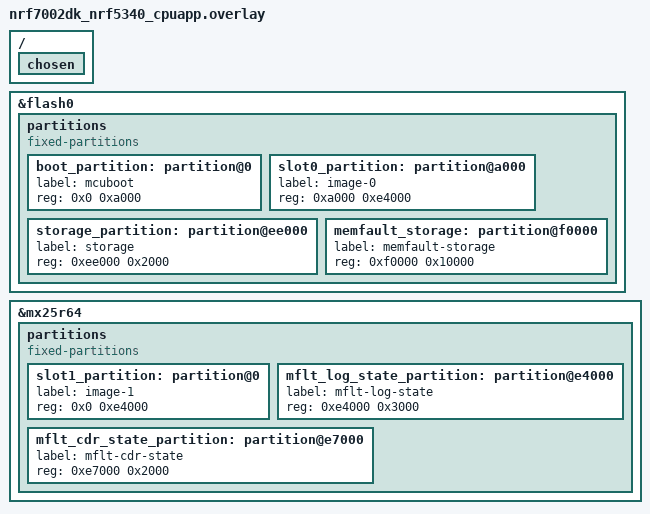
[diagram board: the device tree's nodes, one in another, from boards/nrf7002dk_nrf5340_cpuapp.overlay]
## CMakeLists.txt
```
#
# Copyright (c) 2026 Nordic Semiconductor
#
# SPDX-License-Identifier: LicenseRef-Nordic-5-Clause
#

cmake_minimum_required(VERSION 3.20.0)

# Register zego modules: button, led, wifi, network, wifi_ble_prov, memonitor, ux, ntp, factory_reset.
get_filename_component(ZEGO_BUTTON_DIR ${CMAKE_CURRENT_SOURCE_DIR}/../zego/bricks/button REALPATH)
get_filename_component(ZEGO_LED_DIR ${CMAKE_CURRENT_SOURCE_DIR}/../zego/bricks/led REALPATH)
get_filename_component(ZEGO_WIFI_DIR ${CMAKE_CURRENT_SOURCE_DIR}/../zego/bricks/wifi REALPATH)
get_filename_component(ZEGO_NETWORK_DIR ${CMAKE_CURRENT_SOURCE_DIR}/../zego/bricks/network REALPATH)
get_filename_component(ZEGO_WIFI_BLE_PROV_DIR ${CMAKE_CURRENT_SOURCE_DIR}/../zego/bricks/wifi_ble_prov REALPATH)
get_filename_component(ZEGO_MEMONITOR_DIR ${CMAKE_CURRENT_SOURCE_DIR}/../zego/bricks/memonitor REALPATH)
get_filename_component(ZEGO_UX_DIR ${CMAKE_CURRENT_SOURCE_DIR}/../zego/bricks/ux REALPATH)
get_filename_component(ZEGO_NTP_DIR ${CMAKE_CURRENT_SOURCE_DIR}/../zego/bricks/ntp REALPATH)
get_filename_component(ZEGO_FACTORY_RESET_DIR ${CMAKE_CURRENT_SOURCE_DIR}/../zego/bricks/factory_reset REALPATH)
list(APPEND EXTRA_ZEPHYR_MODULES ${ZEGO_BUTTON_DIR} ${ZEGO_LED_DIR} ${ZEGO_WIFI_DIR} ${ZEGO_NETWORK_DIR} ${ZEGO_WIFI_BLE_PROV_DIR} ${ZEGO_MEMONITOR_DIR} ${ZEGO_UX_DIR} ${ZEGO_NTP_DIR} ${ZEGO_FACTORY_RESET_DIR})

find_package(Zephyr REQUIRED HINTS $ENV{ZEPHYR_BASE})
project(memfault-nrf7002dk)

# Generate hex files from pem files for app HTTPS client
if(CONFIG_APP_HTTPS_CLIENT_MODULE)
    set(gen_dir ${CMAKE_CURRENT_BINARY_DIR}/certs)
    zephyr_include_directories(${gen_dir})
    generate_inc_file_for_target(
        app
        src/modules/app_https_client/cert/Comodo-AAA-Certificate-Services.pem
        ${gen_dir}/Comodo-AAA-Certificate-Services.pem.inc
    )
endif()


zephyr_include_directories(${CMAKE_CURRENT_SOURCE_DIR}/src)
zephyr_include_directories(${CMAKE_CURRENT_SOURCE_DIR}/src/modules/app_memfault/config)

# APP_VERSION_STRING, PRD_VERSION, SPECS_VERSION set by zego/wifi/CMakeLists.txt
target_sources(app PRIVATE src/main.c)

# Module subdirectories (SMF+zbus modular architecture)
# button module now provided by zego/button (EXTRA_ZEPHYR_MODULES above)
# Shared network module provided by zego/network (EXTRA_ZEPHYR_MODULES above);
# app shim (net_event_mgmt.c) defines NETWORK_CHAN, declares WIFI_CHAN, overrides weak callbacks.
if(CONFIG_ZEGO_NETWORK)
    add_subdirectory(src/modules/network)
endif()
if(CONFIG_ZEGO_UX)
    add_subdirectory(src/modules/ux)
endif()
if(CONFIG_APP_MEMFAULT_MODULE)
    add_subdirectory(src/modules/app_memfault)
endif()
if(CONFIG_APP_HTTPS_CLIENT_MODULE)
    add_subdirectory(src/modules/app_https_client)
endif()
if(CONFIG_APP_MQTT_CLIENT_MODULE)
    add_subdirectory(src/modules/app_mqtt_client)
endif()

# ntp module now provided by zego/ntp (EXTRA_ZEPHYR_MODULES above); app shim
# (net_event_mgmt.c) publishes ZEGO_NTP_NET_CHAN from its weak-hook overrides.

# zego/wifi_ble_prov handles BLE provisioning as an EXTRA_ZEPHYR_MODULE (no extra target_link_libraries needed).
# zego/led is registered above and provides LED_CMD_CHAN; consumed by zego/ux.
```

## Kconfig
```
#
# Copyright (c) 2026 Nordic Semiconductor ASA
#
# SPDX-License-Identifier: LicenseRef-Nordic-5-Clause
#

menu "Application configuration"

module = APP_MAIN
module-str = Application main
source "${ZEPHYR_BASE}/subsys/logging/Kconfig.template.log_config"

rsource "src/modules/button/Kconfig.button"
rsource "src/modules/network/Kconfig"
rsource "src/modules/heap_monitor/Kconfig.heap_monitor"
rsource "src/modules/wifi_prov_over_ble/Kconfig.wifi_prov_over_ble"
rsource "src/modules/app_memfault/Kconfig.app_memfault"
rsource "src/modules/app_https_client/Kconfig.app_https_client"
rsource "src/modules/app_mqtt_client/Kconfig.app_mqtt_client"
rsource "src/modules/ntp/Kconfig.ntp"

rsource "src/modules/network/Kconfig.defaults"
rsource "src/modules/heap_monitor/Kconfig.defaults"
rsource "src/modules/wifi_prov_over_ble/Kconfig.defaults"
rsource "src/modules/app_memfault/Kconfig.defaults"
rsource "src/modules/app_https_client/Kconfig.defaults"
rsource "src/modules/app_mqtt_client/Kconfig.defaults"
rsource "src/modules/ntp/Kconfig.defaults"

endmenu

source "Kconfig.zephyr"
```

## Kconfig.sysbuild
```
#
# Copyright (c) 2024 Nordic Semiconductor
#
# SPDX-License-Identifier: LicenseRef-Nordic-5-Clause
#

config WIFI_NRF70
	bool
	default y if BOARD_NRF7002DK_NRF5340_CPUAPP

# Tells sysbuild's netcore-image choice (nrf/sysbuild/Kconfig.netcore) to
# default to NETCORE_HCI_IPC on boards with a separate network core
# (nRF7002DK/nRF5340). Without this, sysbuild silently falls back to
# NETCORE_NONE and no BLE controller firmware is built for the network
# core, even though the app enables CONFIG_BT_HCI_IPC for BLE Wi-Fi
# provisioning — every reference NCS Bluetooth sample sets this in its
# own Kconfig.sysbuild (e.g. nrf/samples/bluetooth/peripheral_uart).
config NRF_DEFAULT_BLUETOOTH
	default y

# nrf/sysbuild/Kconfig.netcore only ships a built-in NETCORE_REMOTE_BOARD_NAME
# default for nrf5340dk/thingy53 — not nrf7002dk, even though nrf7002dk's
# nRF5340 is netcore-capable (SUPPORT_NETCORE already defaults to y for it).
# Without this, NETCORE_REMOTE_BOARD_NAME stays "" so the NETCORE choice's
# "if NRF_DEFAULT_BLUETOOTH && NETCORE_REMOTE_BOARD_NAME != \"\"" guard never
# matches and sysbuild falls back to NETCORE_NONE. This symbol has no Kconfig
# prompt, so it can only be set via a `default`, not a sysbuild.conf fragment.
config NETCORE_REMOTE_BOARD_NAME
	default "nrf7002dk_nrf5340_cpunet" if $(BOARD) = "nrf7002dk_nrf5340_cpuapp"

source "share/sysbuild/Kconfig"
```

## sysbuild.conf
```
#
# Copyright (c) 2025 Nordic Semiconductor ASA
#
# SPDX-License-Identifier: LicenseRef-Nordic-5-Clause
#

SB_CONFIG_BOOTLOADER_MCUBOOT=y
SB_CONFIG_PARTITION_MANAGER=n
SB_CONFIG_MERGED_HEX_FILES=y

# nRF5340 (nrf7002dk) only: the BLE controller runs on the network core
# over IPC. Build the upstream Zephyr hci_ipc sample as the netcore image
# so the Wi-Fi provisioning over BLE module can open the HCI driver.
# On nrf54lm20dk SUPPORT_NETCORE=n (single-core SoC), so this setting
# has no effect there and produces a benign Kconfig choice warning.
# kconfiglib prohibits 'select' on choice symbols, so this assignment cannot
# be made board-conditional from Kconfig.sysbuild.  The warning is harmless:
# sysbuild skips the hci_ipc image whenever SUPPORT_NETCORE=n, regardless of
# this choice assignment.  See also the MBEDTLS_PSA_CRYPTO_EXTERNAL_RNG note
# in boards/nrf7002dk_nrf5340_cpuapp.conf — same class of unfixable warning.
SB_CONFIG_NETCORE_HCI_IPC=y
```

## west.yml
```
manifest:
  version: "0.13"

  defaults:
    remote: ncs

  remotes:
    - name: ncs
      url-base: https://github.com/nrfconnect
    - name: chshzh
      url-base: https://github.com/chshzh

  projects:
    # NCS v3.4.1 — imports zephyr, bootloader, modules, nrfxlib, tools, etc.
    - name: sdk-nrf
      path: nrf
      revision: v3.4.1
      import: true
      remote: ncs
      
    # Common app modules and libraries
    - name: zego
      path: zego
      revision: v3.4.1.0
      remote: chshzh

    # Add more sibling projects as needed:
    # - name: nordic-wifi-webdash
    #   path: nordic-wifi-webdash
    #   revision: main
    #   remote: chshzh

    # - name: nordic-wifi-audio
    #   path: nordic-wifi-audio
    #   revision: main
    #   remote: chshzh

    # - name: claude
    #   path: .claude
    #   revision: main
    #   remote: chshzh
    
    - name: zview
      url: https://github.com/chshzh/zview
      revision: main
      path: modules/tools/zview
      west-commands: scripts/west-commands.yml
    

  self:
    path: nordic-wifi-memfault
```

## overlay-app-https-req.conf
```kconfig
# App HTTPS Request Test overlay configuration
# Use this overlay to enable periodic HTTPS client requests

# Enable app HTTPS client functionality
CONFIG_APP_HTTPS_CLIENT_ENABLED=y

# Configure HTTPS hostname and interval
CONFIG_APP_HTTPS_HOSTNAME="example.com"
CONFIG_APP_HTTPS_REQUEST_INTERVAL_SEC=300

# App HTTPS client logging
CONFIG_APP_HTTPS_CLIENT_LOG_LEVEL_INF=y

# mbedTLS requirements for example.com (Cloudflare-hosted, cert chain via Comodo AAA root)
# RSA: needed to verify Comodo AAA root signature (RSA/SHA1 root CA)
CONFIG_MBEDTLS_RSA_C=y
# secp384r1: needed to verify P-384 ECC key in SSL.com TLS Transit ECC CA R2
CONFIG_MBEDTLS_ECP_DP_SECP384R1_ENABLED=y
# SNI: required for Cloudflare shared-IP hosting to present the correct certificate
CONFIG_MBEDTLS_SSL_SERVER_NAME_INDICATION=y
```

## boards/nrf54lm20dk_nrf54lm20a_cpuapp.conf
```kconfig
#
# Copyright (c) 2026 Nordic Semiconductor ASA
#
# SPDX-License-Identifier: LicenseRef-Nordic-5-Clause
#

# Configuration coverage priority:
# Command line > Overlay files > project boards/<board>.conf > prj.conf > Board defconfig
# (highest)                                                              (lowest)


# This file contains only:
#   - System-level configuration that belongs to no single module
#   - Module enable/disable flags
#   - Log-level choices (cannot be set via Kconfig.defaults)
#   - Project-specific overrides that differ from module defaults
#   - Shared cross-module settings (TLS, mbedTLS)
#   - Hardware-specific memory and stack tuning
# Module-specific defaults live in each module's Kconfig.defaults file.

# nRF7002EB2 on nRF54LM20DK does not wire the SR coexistence RF switch.
CONFIG_NRF70_SR_COEX=n
CONFIG_NRF70_SR_COEX_RF_SWITCH=n

# nRF54LM20A uses RRAMC, not NVMC. The NCS flash backend
# (memfault_flash_coredump_storage.c) calls nrfx_nvmc directly and will not
# compile for this target — disable it and use the upstream RRAM backend
# (memfault_rram_backed_coredump.c) instead. That backend uses NRFX_RRAMC
# (available on nRF54LX) and reads/writes via direct memory-mapped access +
# nrf_rramc_config_set() with 16-byte (128-bit wordline) buffered writes.
# The partition must be named "memfault_coredump_partition" in pm_static.
CONFIG_MEMFAULT_NCS_INTERNAL_FLASH_BACKED_COREDUMP=n
# Renamed from CONFIG_MEMFAULT_COREDUMP_STORAGE_RRAM in the bundled Memfault SDK
# (now Nordic-specific: CONFIG_MEMFAULT_COREDUMP_STORAGE_NRF_RRAM).
CONFIG_MEMFAULT_COREDUMP_STORAGE_NRF_RRAM=y

# MPSL (Multiprotocol Service Layer) registers RADIO/TIMER/RTC interrupts at
# priority 0 with IRQ_ZERO_LATENCY so they bypass arch_irq_lock()/BASEPRI.
# On this single-core SoC those ISRs can fire inside a K_SPINLOCK block and
# change _current before z_spin_unlock_valid() completes its owner check,
# causing a false-positive "Not my spinlock" assert (RESETREAS=0x80 lockup).
# This does not occur on nRF7002DK where BLE runs on the separate CPUNET core.
# CONFIG_SPIN_VALIDATE is a debug-only feature (Zephyr docs: "adds relatively
# hefty overhead") — disable it for this target so the assert cannot fire.
CONFIG_SPIN_VALIDATE=n

# Wi-Fi provisioning over BLE uses 1M PHY only; 2M PHY is never negotiated
# and can be removed to save controller flash and RAM.
CONFIG_BT_CTLR_PHY_2M=n


# Shell - enabled for Wi-Fi diagnostics (CONFIG_MEMFAULT_SHELL=y disabled to save flash)
CONFIG_SHELL=y
CONFIG_NET_L2_WIFI_SHELL=y
CONFIG_SHELL_STACK_SIZE=8192

# Zego button + LED modules (nRF54LM20DK has enough flash)
CONFIG_ZEGO_BUTTON=y
CONFIG_ZEGO_BUTTON_NUM_BUTTONS=3
CONFIG_ZEGO_BUTTON_BACKEND_DK=y

CONFIG_ZEGO_LED=y
CONFIG_ZEGO_LED_NUM_LEDS=4
CONFIG_ZEGO_LED_BACKEND_DK=y

# memonitor: UART periodic log enabled on nRF54LM20DK (2 MB RRAM — flash headroom available).
# Left n in prj.conf for nRF7002DK where flash is at ~99%.
# CONFIG_ZEGO_MEMONITOR_LOG_PERIODIC=y
```

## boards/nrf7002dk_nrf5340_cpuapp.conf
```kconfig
#
# Copyright (c) 2026 Nordic Semiconductor ASA
#
# SPDX-License-Identifier: LicenseRef-Nordic-5-Clause
#
# Board-specific overrides for nRF7002DK (nRF5340 + nRF7002).
# Contains only settings that differ from prj.conf for this hardware.
# Configuration coverage priority:
# Command line > Overlay files > project boards/<board>.conf > prj.conf > Board defconfig
# (highest)

# Flash-backed coredump using the DTS `memfault_storage` partition (64 KB).
# CONFIG_MEMFAULT_NCS_INTERNAL_FLASH_BACKED_COREDUMP cannot be selected because
# it depends on PARTITION_MANAGER_ENABLED, which is not used for this board.
# The implementation is copied to src/modules/app_memfault/core/ to bypass the
# Kconfig dependency — the actual C code only requires PARTITION_* DTS macros.
CONFIG_MEMFAULT_COREDUMP_STORAGE_CUSTOM=y

# nRF7002DK: 2 user buttons (SW0 = Button 1, SW1 = Button 2), 2 LEDs
CONFIG_ZEGO_BUTTON=y
CONFIG_ZEGO_BUTTON_NUM_BUTTONS=2
CONFIG_ZEGO_BUTTON_BACKEND_DK=y

CONFIG_ZEGO_LED=y
CONFIG_ZEGO_LED_NUM_LEDS=2
CONFIG_ZEGO_LED_BACKEND_DK=y

# ============================================================================
# Silence the v3.3.0 Kconfig warning:
#   "MBEDTLS_PSA_CRYPTO_EXTERNAL_RNG_ALLOW_NON_CSPRNG was assigned the value
#    'y' but got the value 'n'"
# The nrf7002dk_nrf5340_cpuapp_defconfig sets this symbol to 'y'.
# NRF_SECURITY selects DISABLE_MBEDTLS_BUILTIN and sets
# MBEDTLS_CFG_FILE="nrf-config.h", making the Kconfig.mbedtls menu
# (depends on MBEDTLS_BUILTIN && MBEDTLS_CFG_FILE="config-mbedtls.h")
# invisible.  The dependency is therefore unmet.  Explicitly clearing the
# symbol here overrides the defconfig assignment so the assigned value ('n')
# matches the evaluated value ('n').
#
# A related warning ("The choice symbol MBEDTLS_PSA_CRYPTO_EXTERNAL_RNG was
# selected (set =y) but no symbol ended up as the choice selection") also
# originates from the board defconfig and cannot be silenced at the app
# level: kconfiglib does not honour "# CONFIG_CHOICE_SYMBOL is not set" for
# choice symbols, so the defconfig's choice assignment persists.  This is a
# known upstream issue (NRF_SECURITY overrides the choice via CMake, but the
# Kconfig layer is left inconsistent).  The warning is harmless; nrf_security
# always provides its own RNG implementation regardless of this choice.
# ============================================================================
# CONFIG_MBEDTLS_PSA_CRYPTO_EXTERNAL_RNG_ALLOW_NON_CSPRNG is not set
```

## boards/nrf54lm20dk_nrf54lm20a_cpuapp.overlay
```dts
/*
 * Copyright (c) 2026 Nordic Semiconductor ASA
 *
 * SPDX-License-Identifier: LicenseRef-Nordic-5-Clause
 */

&cpuapp_rram {
	/delete-node/ partitions;

	partitions {
		compatible = "fixed-partitions";
		#address-cells = <1>;
		#size-cells = <1>;

		boot_partition: partition@0 {
			label = "mcuboot";
			reg = <0x0 0x10000>;
		};

		slot0_partition: partition@10000 {
			label = "image-0";
			reg = <0x10000 0x1c3000>;
		};

		storage_partition: partition@1d3000 {
			label = "storage";
			reg = <0x1d3000 0x2000>;
		};

		memfault_coredump_partition: partition@1d5000 {
			label = "memfault-coredump-partition";
			reg = <0x1d5000 0x10000>;
		};
	};
};

&mx25r64 {
	status = "okay";
	/delete-node/ partitions;

	partitions {
		compatible = "fixed-partitions";
		#address-cells = <1>;
		#size-cells = <1>;

		slot1_partition: partition@0 {
			label = "image-1";
			reg = <0x0 0x1c3000>;
		};

		/* 12 KB dedicated partition for Memfault disconnect-time log-state blob (must fit 16 B hdr + ~80 B context + 8192 B storage) */
		mflt_log_state_partition: partition@1c3000 {
			label = "mflt-log-state";
			reg = <0x1c3000 0x3000>;
		};

		/* 8 KB dedicated partition for Memfault disconnect-time CDR (WiFi stats) blob */
		mflt_cdr_state_partition: partition@1c6000 {
			label = "mflt-cdr-state";
			reg = <0x1c6000 0x2000>;
		};
	};
};
```

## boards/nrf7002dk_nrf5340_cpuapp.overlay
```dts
/*
 * Copyright (c) 2023 Nordic Semiconductor ASA
 *
 * SPDX-License-Identifier: LicenseRef-Nordic-5-Clause
 */

/ {
	chosen {
		/delete-property/ zephyr,ipc_shm;
	};
};

&flash0 {
	/delete-node/ partitions;

	partitions {
		compatible = "fixed-partitions";
		#address-cells = <1>;
		#size-cells = <1>;

		boot_partition: partition@0 {
			label = "mcuboot";
			reg = <0x0 0xa000>;
		};

		slot0_partition: partition@a000 {
			label = "image-0";
			reg = <0xa000 0xe4000>;
		};

		storage_partition: partition@ee000 {
			label = "storage";
			reg = <0xee000 0x2000>;
		};

		memfault_storage: partition@f0000 {
			label = "memfault-storage";
			reg = <0xf0000 0x10000>;
		};
	};
};

&mx25r64 {
	status = "okay";
	/delete-node/ partitions;

	partitions {
		compatible = "fixed-partitions";
		#address-cells = <1>;
		#size-cells = <1>;

		slot1_partition: partition@0 {
			label = "image-1";
			reg = <0x0 0xe4000>; /* must match slot0 for MCUBoot swap */
		};

		/* 12 KB dedicated partition for Memfault disconnect-time log-state blob (must fit 16 B hdr + ~80 B context + 8192 B storage) */
		mflt_log_state_partition: partition@e4000 {
			label = "mflt-log-state";
			reg = <0xe4000 0x3000>;
		};

		/* 8 KB dedicated partition for Memfault disconnect-time CDR (WiFi stats) blob */
		mflt_cdr_state_partition: partition@e7000 {
			label = "mflt-cdr-state";
			reg = <0xe7000 0x2000>;
		};
	};
};
```

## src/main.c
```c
/*
 * Copyright (c) 2026 Nordic Semiconductor ASA
 *
 * SPDX-License-Identifier: LicenseRef-Nordic-5-Clause
 *
 * Application entry point. This file is intentionally neutral — all feature
 * logic lives in modules under src/modules/ and starts via SYS_INIT / zbus.
 */

#include <ctype.h>
#include <zephyr/kernel.h>
#include <zephyr/logging/log.h>
#include <zephyr/net/net_if.h>

LOG_MODULE_REGISTER(main, CONFIG_APP_MAIN_LOG_LEVEL);

int main(void)
{
	struct net_if *iface = net_if_get_default();
	struct net_linkaddr *mac_addr =
		iface ? net_if_get_link_addr(iface) : NULL;

	LOG_INF("==============================================");
	LOG_INF("Board:   %s", CONFIG_BOARD);
#if defined(CONFIG_MEMFAULT_NCS_FW_VERSION)
	LOG_INF("Version: %s", CONFIG_MEMFAULT_NCS_FW_VERSION);
#endif
	LOG_INF("Build:   %s %s", __DATE__, __TIME__);
	if (mac_addr && mac_addr->len == 6) {
		LOG_INF("MAC: %02X:%02X:%02X:%02X:%02X:%02X",
			mac_addr->addr[0], mac_addr->addr[1], mac_addr->addr[2],
			mac_addr->addr[3], mac_addr->addr[4], mac_addr->addr[5]);
	}
	LOG_INF("----------------------------------------------");
	LOG_INF("Enabled modules:");

	/* Input */
#if CONFIG_BUTTON_MODULE
	LOG_INF("  [input]  button");
#endif
	/* CONFIG_LED_MODULE_ENABLED not yet implemented */

	/* WiFi */
#if CONFIG_WIFI_STA_PROV_OVER_BLE_ENABLED
	LOG_INF("  [wifi]   wifi_sta_prov_over_ble");
#endif
	/* CONFIG_WIFI_STA_STATIC_ENABLED   not yet implemented */
	/* CONFIG_WIFI_STA_CRED_SHELL_ENABLED not yet implemented */
	/* CONFIG_WIFI_DIRECT_GO_ENABLED     not yet implemented */
	/* CONFIG_WIFI_DIRECT_CLI_ENABLED    not yet implemented */

	/* Application */
#if CONFIG_HEAPS_MONITOR
	LOG_INF("  [app]    heap_monitor");
#endif
#if CONFIG_APP_MEMFAULT_MODULE
	LOG_INF("  [app]    app_memfault");
#endif
#if CONFIG_APP_HTTPS_CLIENT_MODULE
	LOG_INF("  [app]    app_https_client  (host: %s, interval: %ds)",
		CONFIG_APP_HTTPS_HOSTNAME, CONFIG_APP_HTTPS_REQUEST_INTERVAL_SEC);
#endif
#if CONFIG_APP_MQTT_CLIENT_MODULE
	LOG_INF("  [app]    app_mqtt_client   (broker: %s, interval: %ds)",
		CONFIG_APP_MQTT_CLIENT_BROKER_HOSTNAME,
		CONFIG_APP_MQTT_CLIENT_PUBLISH_INTERVAL_SEC);
#endif
#if CONFIG_NTP_MODULE_ENABLED
	LOG_INF("  [app]    ntp               (server: %s)", CONFIG_NTP_MODULE_SERVER);
#endif
	LOG_INF("==============================================");

	for (;;) {
		k_sleep(K_FOREVER);
	}
	return 0;
}
```

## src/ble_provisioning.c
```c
/*
 * Copyright (c) 2025 Nordic Semiconductor ASA
 *
 * SPDX-License-Identifier: LicenseRef-Nordic-5-Clause
 */

#include "ble_provisioning.h"
#include <zephyr/types.h>
#include <stddef.h>
#include <string.h>
#include <errno.h>
#include <zephyr/sys/printk.h>
#include <zephyr/kernel.h>
#include <zephyr/bluetooth/bluetooth.h>
#include <zephyr/bluetooth/hci.h>
#include <zephyr/bluetooth/conn.h>
#include <zephyr/bluetooth/uuid.h>
#include <zephyr/bluetooth/gatt.h>

#include <zephyr/net/wifi.h>
#include <zephyr/net/wifi_mgmt.h>
#include <zephyr/net/wifi_credentials.h>
#include <zephyr/net/net_mgmt.h>
#include <zephyr/net/net_if.h>

#include <net/wifi_prov_core/wifi_prov_core.h>
#include <bluetooth/services/wifi_provisioning.h>

#include <zephyr/logging/log.h>
LOG_MODULE_REGISTER(ble_prov, CONFIG_MEMFAULT_SAMPLE_LOG_LEVEL);

#define WIFI_RECONNECT_DELAY_SEC 5
/* Retry every 3 minutes if reconnect fails */
#define WIFI_RECONNECT_RETRY_SEC 180

#ifdef CONFIG_WIFI_PROV_ADV_DATA_UPDATE
#define ADV_DATA_UPDATE_INTERVAL CONFIG_WIFI_PROV_ADV_DATA_UPDATE_INTERVAL
#endif /* CONFIG_WIFI_PROV_ADV_DATA_UPDATE */

#define ADV_PARAM_UPDATE_DELAY 1

#define ADV_DATA_VERSION_IDX          (BT_UUID_SIZE_128 + 0)
#define ADV_DATA_FLAG_IDX             (BT_UUID_SIZE_128 + 1)
#define ADV_DATA_FLAG_PROV_STATUS_BIT BIT(0)
#define ADV_DATA_FLAG_CONN_STATUS_BIT BIT(1)
#define ADV_DATA_RSSI_IDX             (BT_UUID_SIZE_128 + 3)

#define PROV_BT_LE_ADV_PARAM_FAST                                              \
	BT_LE_ADV_PARAM(BT_LE_ADV_OPT_CONN, BT_GAP_ADV_FAST_INT_MIN_2,         \
			BT_GAP_ADV_FAST_INT_MAX_2, NULL)

#define PROV_BT_LE_ADV_PARAM_SLOW                                              \
	BT_LE_ADV_PARAM(BT_LE_ADV_OPT_CONN, BT_GAP_ADV_SLOW_INT_MIN,           \
			BT_GAP_ADV_SLOW_INT_MAX, NULL)

#define ADV_DAEMON_STACK_SIZE 4096
#define ADV_DAEMON_PRIORITY   5

/* Work item for triggering WiFi connection after provisioning */
static struct k_work_delayable wifi_connect_work;
static bool wifi_connect_requested = false;

/* Track BLE connection state to avoid updating advertising while connected */
static struct bt_conn *current_conn = NULL;

static bool wifi_reconnect_pending = false;

static struct net_mgmt_event_callback wifi_mgmt_cb;

/* Flag to track if we've already requested connection after provisioning */
static bool connection_requested_after_provisioning = false;

/* Flag to indicate if credentials existed at boot time */
static bool credentials_existed_at_boot = false;

/* Track the last known provisioning state to detect new provisioning */
static bool last_prov_state = false;

K_THREAD_STACK_DEFINE(adv_daemon_stack_area, ADV_DAEMON_STACK_SIZE);

static struct k_work_q adv_daemon_work_q;

static uint8_t device_name[] = {'P', 'V', '0', '0', '0', '0', '0', '0'};

static uint8_t prov_svc_data[] = {BT_UUID_PROV_VAL, 0x00, 0x00, 0x00, 0x00};

static const struct bt_data ad[] = {
	BT_DATA_BYTES(BT_DATA_FLAGS, (BT_LE_AD_GENERAL | BT_LE_AD_NO_BREDR)),
	BT_DATA_BYTES(BT_DATA_UUID128_ALL, BT_UUID_PROV_VAL),
	BT_DATA(BT_DATA_NAME_COMPLETE, device_name, sizeof(device_name)),
};

static const struct bt_data sd[] = {
	BT_DATA(BT_DATA_SVC_DATA128, prov_svc_data, sizeof(prov_svc_data)),
};

static struct k_work_delayable update_adv_param_work;
static struct k_work_delayable update_adv_data_work;

static void wifi_mgmt_event_handler(struct net_mgmt_event_callback *cb,
				    uint64_t mgmt_event, struct net_if *iface)
{
	ARG_UNUSED(iface);

	if (!wifi_prov_state_get()) {
		return;
	}

	switch (mgmt_event) {
	case NET_EVENT_WIFI_DISCONNECT_RESULT:
		if (!wifi_reconnect_pending) {
			wifi_reconnect_pending = true;
			k_work_reschedule(&wifi_connect_work,
					  K_SECONDS(WIFI_RECONNECT_DELAY_SEC));
			LOG_INF("WiFi disconnected, scheduling reconnect");
		}
		break;
	case NET_EVENT_WIFI_CONNECT_RESULT:
		wifi_reconnect_pending = false;
		k_work_cancel_delayable(&wifi_connect_work);
		break;
	default:
		break;
	}
}

static void wifi_connect_work_handler(struct k_work *work)
{
	int err;
	struct net_if *iface = net_if_get_default();
	struct wifi_iface_status status = {0};
	int status_rc = net_mgmt(NET_REQUEST_WIFI_IFACE_STATUS, iface, &status,
				 sizeof(status));
	bool wifi_is_connected =
		(status_rc == 0 && status.state >= WIFI_STATE_ASSOCIATED);
	bool wifi_is_connecting =
		(status_rc == 0 && status.state > WIFI_STATE_DISCONNECTED &&
		 status.state < WIFI_STATE_ASSOCIATED);
	bool reconnect_cycle_active = wifi_reconnect_pending;

	if (wifi_is_connected) {
		wifi_reconnect_pending = false;
		return;
	}

	if (wifi_credentials_is_empty()) {
		LOG_WRN("No stored WiFi credentials, skipping reconnect "
			"attempts");
		wifi_reconnect_pending = false;
		return;
	}

	if (wifi_is_connecting) {
		LOG_DBG("WiFi connection already in progress (state %d)",
			status.state);
	} else {
		LOG_INF("WiFi credentials detected, attempting to connect");
		err = net_mgmt(NET_REQUEST_WIFI_CONNECT_STORED, iface, NULL, 0);
		if (err) {
			LOG_WRN("WiFi connection request failed: %d", err);
			if (!reconnect_cycle_active) {
				connection_requested_after_provisioning = false;
			}
		} else {
			LOG_INF("WiFi connection request sent successfully");
		}
	}

	if (reconnect_cycle_active) {
		k_work_reschedule(&wifi_connect_work,
				  K_SECONDS(WIFI_RECONNECT_RETRY_SEC));
		LOG_INF("WiFi still disconnected, retrying in %d seconds",
			WIFI_RECONNECT_RETRY_SEC);
	}
}

static void update_wifi_status_in_adv(void)
{
	int rc;
	struct net_if *iface = net_if_get_default();
	struct wifi_iface_status status = {0};
	bool current_prov_state;

	prov_svc_data[ADV_DATA_VERSION_IDX] = PROV_SVC_VER;

	current_prov_state = wifi_prov_state_get();

	/* Detect new provisioning: state changed from unprovisioned to
	 * provisioned */
	if (current_prov_state && !last_prov_state) {
		LOG_INF("New WiFi provisioning detected");
		/* Reset flags to allow new connection attempt */
		connection_requested_after_provisioning = false;
		credentials_existed_at_boot = false;
	}
	last_prov_state = current_prov_state;

	/* If no config, mark it as unprovisioned. */
	if (!current_prov_state) {
		prov_svc_data[ADV_DATA_FLAG_IDX] &=
			~ADV_DATA_FLAG_PROV_STATUS_BIT;
	} else {
		prov_svc_data[ADV_DATA_FLAG_IDX] |=
			ADV_DATA_FLAG_PROV_STATUS_BIT;

		/* Only trigger connection if:
		 * 1. We haven't already requested connection
		 * 2. Credentials exist
		 * 3. Credentials did NOT exist at boot (meaning they were just
		 * added via BLE)
		 * 4. WiFi is not already connected
		 */
		if (!connection_requested_after_provisioning &&
		    !wifi_credentials_is_empty() &&
		    !credentials_existed_at_boot) {
			rc = net_mgmt(NET_REQUEST_WIFI_IFACE_STATUS, iface,
				      &status, sizeof(status));
			bool wifi_is_connected =
				(rc == 0 &&
				 status.state >= WIFI_STATE_ASSOCIATED);

			if (!wifi_is_connected) {
				connection_requested_after_provisioning = true;
				k_work_reschedule(&wifi_connect_work,
						  K_SECONDS(2));
				LOG_INF("WiFi credentials provisioned, "
					"scheduling connection "
					"attempt");
			}
		}
	}

	rc = net_mgmt(NET_REQUEST_WIFI_IFACE_STATUS, iface, &status,
		      sizeof(struct wifi_iface_status));
	/* If WiFi is not connected or error occurs, mark it as not connected.
	 */
	if ((rc != 0) || (status.state < WIFI_STATE_ASSOCIATED)) {
		prov_svc_data[ADV_DATA_FLAG_IDX] &=
			~ADV_DATA_FLAG_CONN_STATUS_BIT;
		prov_svc_data[ADV_DATA_RSSI_IDX] = INT8_MIN;
	} else {
		/* WiFi is connected. */
		prov_svc_data[ADV_DATA_FLAG_IDX] |=
			ADV_DATA_FLAG_CONN_STATUS_BIT;
		prov_svc_data[ADV_DATA_RSSI_IDX] = status.rssi;
	}
}

static void connected(struct bt_conn *conn, uint8_t err)
{
	char addr[BT_ADDR_LE_STR_LEN];

	if (err) {
		LOG_ERR("BT Connection failed (err 0x%02x)", err);
		return;
	}

	bt_addr_le_to_str(bt_conn_get_dst(conn), addr, sizeof(addr));
	LOG_INF("BT Connected: %s", addr);

	/* Store connection reference and stop advertising updates */
	current_conn = bt_conn_ref(conn);
	k_work_cancel_delayable(&update_adv_data_work);
}

static void disconnected(struct bt_conn *conn, uint8_t reason)
{
	char addr[BT_ADDR_LE_STR_LEN];

	bt_addr_le_to_str(bt_conn_get_dst(conn), addr, sizeof(addr));
	LOG_INF("BT Disconnected: %s (reason 0x%02x)", addr, reason);

	/* Release connection reference */
	if (current_conn) {
		bt_conn_unref(current_conn);
		current_conn = NULL;
	}

	k_work_reschedule_for_queue(&adv_daemon_work_q, &update_adv_param_work,
				    K_SECONDS(ADV_PARAM_UPDATE_DELAY));
	/* Delay ad data update until after advertising restarts to avoid EAGAIN
	 * (-11) */
	k_work_reschedule_for_queue(&adv_daemon_work_q, &update_adv_data_work,
				    K_SECONDS(ADV_PARAM_UPDATE_DELAY + 1));
}

static void identity_resolved(struct bt_conn *conn, const bt_addr_le_t *rpa,
			      const bt_addr_le_t *identity)
{
	char addr_identity[BT_ADDR_LE_STR_LEN];
	char addr_rpa[BT_ADDR_LE_STR_LEN];

	bt_addr_le_to_str(identity, addr_identity, sizeof(addr_identity));
	bt_addr_le_to_str(rpa, addr_rpa, sizeof(addr_rpa));

	LOG_INF("BT Identity resolved %s -> %s", addr_rpa, addr_identity);
}

static void security_changed(struct bt_conn *conn, bt_security_t level,
			     enum bt_security_err err)
{
	char addr[BT_ADDR_LE_STR_LEN];

	bt_addr_le_to_str(bt_conn_get_dst(conn), addr, sizeof(addr));

	if (!err) {
		LOG_INF("BT Security changed: %s level %u", addr, level);
	} else {
		LOG_ERR("BT Security failed: %s level %u err %d", addr, level,
			err);
	}
}

BT_CONN_CB_DEFINE(conn_callbacks) = {
	.connected = connected,
	.disconnected = disconnected,
	.identity_resolved = identity_resolved,
	.security_changed = security_changed,
};

static void auth_cancel(struct bt_conn *conn)
{
	char addr[BT_ADDR_LE_STR_LEN];

	bt_addr_le_to_str(bt_conn_get_dst(conn), addr, sizeof(addr));

	LOG_WRN("BT Pairing cancelled: %s", addr);
}

static struct bt_conn_auth_cb auth_cb_display = {
	.cancel = auth_cancel,
};

static void pairing_complete(struct bt_conn *conn, bool bonded)
{
	char addr[BT_ADDR_LE_STR_LEN];

	bt_addr_le_to_str(bt_conn_get_dst(conn), addr, sizeof(addr));
	LOG_INF("BT pairing completed: %s, bonded: %d", addr, bonded);
}

static void pairing_failed(struct bt_conn *conn, enum bt_security_err reason)
{
	LOG_ERR("BT Pairing Failed (%d). Disconnecting.", reason);
	bt_conn_disconnect(conn, BT_HCI_ERR_AUTH_FAIL);
}

static struct bt_conn_auth_info_cb auth_info_cb_display = {
	.pairing_complete = pairing_complete,
	.pairing_failed = pairing_failed,
};

static void update_adv_data_task(struct k_work *item)
{
	int rc;

	/* Always update WiFi status logic (triggers connection if needed) */
	update_wifi_status_in_adv();

	/* Skip advertisement data updates if we have an active BLE connection
	 * to avoid bt_le_adv_update_data() error -11
	 */
	if (current_conn != NULL) {
		LOG_DBG("Skipping advertisement data update - BLE client "
			"connected");
#ifdef CONFIG_WIFI_PROV_ADV_DATA_UPDATE
		k_work_reschedule_for_queue(
			&adv_daemon_work_q, &update_adv_data_work,
			K_SECONDS(ADV_DATA_UPDATE_INTERVAL));
#endif
		return;
	}

	rc = bt_le_adv_update_data(ad, ARRAY_SIZE(ad), sd, ARRAY_SIZE(sd));
	if (rc != 0 && rc != -EAGAIN) {
		LOG_ERR("Cannot update advertisement data, err = %d", rc);
	} else if (rc == -EAGAIN) {
		LOG_DBG("Advertisement update deferred, advertising not "
			"active");
	}
#ifdef CONFIG_WIFI_PROV_ADV_DATA_UPDATE
	k_work_reschedule_for_queue(&adv_daemon_work_q, &update_adv_data_work,
				    K_SECONDS(ADV_DATA_UPDATE_INTERVAL));
#endif /* CONFIG_WIFI_PROV_ADV_DATA_UPDATE */
}

static void update_adv_param_task(struct k_work *item)
{
	int rc;

	rc = bt_le_adv_stop();
	if (rc != 0) {
		LOG_ERR("Cannot stop advertisement: err = %d", rc);
		return;
	}

	rc = bt_le_adv_start(prov_svc_data[ADV_DATA_FLAG_IDX] &
					     ADV_DATA_FLAG_PROV_STATUS_BIT
				     ? PROV_BT_LE_ADV_PARAM_SLOW
				     : PROV_BT_LE_ADV_PARAM_FAST,
			     ad, ARRAY_SIZE(ad), sd, ARRAY_SIZE(sd));
	if (rc != 0) {
		LOG_ERR("Cannot start advertisement: err = %d", rc);
	}
}

static void byte_to_hex(char *ptr, uint8_t byte, char base)
{
	int i, val;

	for (i = 0, val = (byte & 0xf0) >> 4; i < 2; i++, val = byte & 0x0f) {
		if (val < 10) {
			*ptr++ = (char)(val + '0');
		} else {
			*ptr++ = (char)(val - 10 + base);
		}
	}
}

static void update_dev_name(struct net_linkaddr *mac_addr)
{
	byte_to_hex(&device_name[2], mac_addr->addr[3], 'A');
	byte_to_hex(&device_name[4], mac_addr->addr[4], 'A');
	byte_to_hex(&device_name[6], mac_addr->addr[5], 'A');
}

int ble_prov_init(void)
{
	int rc;
	struct net_if *iface = net_if_get_default();
	struct net_linkaddr *mac_addr = net_if_get_link_addr(iface);
	char device_name_str[sizeof(device_name) + 1];

	/* Check if credentials already exist at boot time */
	credentials_existed_at_boot = !wifi_credentials_is_empty();
	last_prov_state = wifi_prov_state_get();

	if (credentials_existed_at_boot) {
		/* Mark connection as already requested since main.c handles it
		 */
		connection_requested_after_provisioning = true;
		LOG_INF("WiFi credentials exist at boot, skipping BLE "
			"auto-connect");
	}

	bt_conn_auth_cb_register(&auth_cb_display);
	bt_conn_auth_info_cb_register(&auth_info_cb_display);

	rc = bt_enable(NULL);
	if (rc) {
		LOG_ERR("Bluetooth init failed (err %d)", rc);
		return rc;
	}

	LOG_INF("Bluetooth initialized");

	rc = wifi_prov_init();
	if (rc == 0) {
		LOG_INF("Wi-Fi provisioning service starts successfully");
	} else {
		LOG_ERR("Error initializing Wi-Fi provisioning service");
		return rc;
	}

	/* Prepare advertisement data */
	if (mac_addr) {
		update_dev_name(mac_addr);
	}
	device_name_str[sizeof(device_name_str) - 1] = '\0';
	memcpy(device_name_str, device_name, sizeof(device_name));
	bt_set_name(device_name_str);

	rc = bt_le_adv_start(prov_svc_data[ADV_DATA_FLAG_IDX] &
					     ADV_DATA_FLAG_PROV_STATUS_BIT
				     ? PROV_BT_LE_ADV_PARAM_SLOW
				     : PROV_BT_LE_ADV_PARAM_FAST,
			     ad, ARRAY_SIZE(ad), sd, ARRAY_SIZE(sd));
	if (rc) {
		LOG_ERR("BT Advertising failed to start (err %d)", rc);
		return rc;
	}
	LOG_INF("BT Advertising successfully started");

	update_wifi_status_in_adv();

	/* Register WiFi management event handler for reconnect logic */
	net_mgmt_init_event_callback(&wifi_mgmt_cb, wifi_mgmt_event_handler,
				     NET_EVENT_WIFI_DISCONNECT_RESULT |
					     NET_EVENT_WIFI_CONNECT_RESULT);
	net_mgmt_add_event_callback(&wifi_mgmt_cb);

	k_work_queue_init(&adv_daemon_work_q);
	k_work_queue_start(&adv_daemon_work_q, adv_daemon_stack_area,
			   K_THREAD_STACK_SIZEOF(adv_daemon_stack_area),
			   ADV_DAEMON_PRIORITY, NULL);

	k_work_init_delayable(&wifi_connect_work, wifi_connect_work_handler);
	k_work_init_delayable(&update_adv_param_work, update_adv_param_task);
	k_work_init_delayable(&update_adv_data_work, update_adv_data_task);
#ifdef CONFIG_WIFI_PROV_ADV_DATA_UPDATE
	k_work_schedule_for_queue(&adv_daemon_work_q, &update_adv_data_work,
				  K_SECONDS(ADV_DATA_UPDATE_INTERVAL));
#endif /* CONFIG_WIFI_PROV_ADV_DATA_UPDATE */

	return 0;
}

void ble_prov_update_wifi_status(bool connected)
{
	/* Reset connection request flag when WiFi connects */
	if (connected) {
		wifi_connect_requested = false;
		wifi_reconnect_pending = false;
	}

	/* Update advertisement data with current WiFi status */
	k_work_reschedule_for_queue(&adv_daemon_work_q, &update_adv_data_work,
				    K_NO_WAIT);
}
```

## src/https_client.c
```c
/*
 * Copyright (c) 2026 Nordic Semiconductor ASA
 *
 * SPDX-License-Identifier: LicenseRef-Nordic-5-Clause
 */

#include "https_client.h"

#include <string.h>
#include <zephyr/kernel.h>
#include <stdlib.h>
#include <zephyr/net/socket.h>
#include <zephyr/net/tls_credentials.h>
#include <zephyr/logging/log.h>
#include <memfault/metrics/metrics.h>

#if defined(CONFIG_POSIX_API)
#include <zephyr/posix/arpa/inet.h>
#include <zephyr/posix/netdb.h>
#include <zephyr/posix/unistd.h>
#include <zephyr/posix/sys/socket.h>
#endif

#if CONFIG_MODEM_KEY_MGMT
#include <modem/modem_key_mgmt.h>
#endif

LOG_MODULE_REGISTER(https_client_app, CONFIG_HTTPS_CLIENT_LOG_LEVEL);

#define HTTPS_PORT "443"
#define HTTP_HEAD                                                              \
	"HEAD / HTTP/1.1\r\n"                                                  \
	"Host: " CONFIG_HTTPS_HOSTNAME ":" HTTPS_PORT "\r\n"                   \
	"Connection: close\r\n\r\n"

#define HTTP_HEAD_LEN (sizeof(HTTP_HEAD) - 1)
#define HTTP_HDR_END  "\r\n\r\n"

#define RECV_BUF_SIZE 2048
#define TLS_SEC_TAG   42

#define HTTPS_REQUEST_INTERVAL_SEC CONFIG_HTTPS_REQUEST_INTERVAL_SEC
#define DNS_CHECK_INTERVAL_SEC     10
static const char send_buf[] = HTTP_HEAD;
static char recv_buf[RECV_BUF_SIZE];
static K_SEM_DEFINE(https_thread_sem, 0, 1);
static bool https_client_running = false;
static bool network_ready = false;
static uint32_t https_req_total;    /* Local counter for total requests */
static uint32_t https_req_failures; /* Local counter for failed requests */

/* Certificate for hostname */
static const char cert[] = {
#include "Comodo-AAA-Certificate-Services.pem.inc"

	/* Null terminate certificate if running Mbed TLS on the application
	 * core. Required by TLS credentials API.
	 */
	IF_ENABLED(CONFIG_TLS_CREDENTIALS, (0x00)) };

BUILD_ASSERT(sizeof(cert) < KB(4), "Certificate too large");

/* Provision certificate to modem */
static int cert_provision(void)
{
	int err;

	LOG_INF("Provisioning certificate");

#if CONFIG_MODEM_KEY_MGMT
	bool exists;
	int mismatch;

	/* It may be sufficient for you application to check whether the correct
	 * certificate is provisioned with a given tag directly using
	 * modem_key_mgmt_cmp(). Here, for the sake of the completeness, we
	 * check that a certificate exists before comparing it with what we
	 * expect it to be.
	 */
	err = modem_key_mgmt_exists(TLS_SEC_TAG,
				    MODEM_KEY_MGMT_CRED_TYPE_CA_CHAIN, &exists);
	if (err) {
		LOG_ERR("Failed to check for certificates err %d", err);
		return err;
	}

	if (exists) {
		mismatch = modem_key_mgmt_cmp(TLS_SEC_TAG,
					      MODEM_KEY_MGMT_CRED_TYPE_CA_CHAIN,
					      cert, sizeof(cert));
		if (!mismatch) {
			LOG_INF("Certificate match");
			return 0;
		}

		LOG_INF("Certificate mismatch");
		err = modem_key_mgmt_delete(TLS_SEC_TAG,
					    MODEM_KEY_MGMT_CRED_TYPE_CA_CHAIN);
		if (err) {
			LOG_ERR("Failed to delete existing certificate, err %d",
				err);
		}
	}

	LOG_INF("Provisioning certificate to the modem");

	/*  Provision certificate to the modem */
	err = modem_key_mgmt_write(TLS_SEC_TAG,
				   MODEM_KEY_MGMT_CRED_TYPE_CA_CHAIN, cert,
				   sizeof(cert));
	if (err) {
		LOG_ERR("Failed to provision certificate, err %d", err);
		return err;
	}
#else  /* CONFIG_MODEM_KEY_MGMT */
	err = tls_credential_add(TLS_SEC_TAG, TLS_CREDENTIAL_CA_CERTIFICATE,
				 cert, sizeof(cert));
	if (err == -EEXIST) {
		LOG_INF("CA certificate already exists, sec tag: %d",
			TLS_SEC_TAG);
	} else if (err < 0) {
		LOG_ERR("Failed to register CA certificate: %d", err);
		return err;
	}
#endif /* !CONFIG_MODEM_KEY_MGMT */

	return 0;
}

/* Setup TLS options on a given socket */
static int tls_setup(int fd)
{
	int err;
	int verify;

	/* Security tag that we have provisioned the certificate with */
	const sec_tag_t tls_sec_tag[] = {
		TLS_SEC_TAG,
	};

	/* Set up TLS peer verification */
	enum {
		NONE = 0,
		OPTIONAL = 1,
		REQUIRED = 2,
	};

	verify = REQUIRED;

	err = setsockopt(fd, SOL_TLS, TLS_PEER_VERIFY, &verify, sizeof(verify));
	if (err) {
		LOG_ERR("Failed to setup peer verification, err %d", errno);
		return err;
	}

	/* Associate the socket with the security tag
	 * we have provisioned the certificate with.
	 */
	err = setsockopt(fd, SOL_TLS, TLS_SEC_TAG_LIST, tls_sec_tag,
			 sizeof(tls_sec_tag));
	if (err) {
		LOG_ERR("Failed to setup TLS sec tag, err %d", errno);
		return err;
	}

	err = setsockopt(fd, SOL_TLS, TLS_HOSTNAME, CONFIG_HTTPS_HOSTNAME,
			 sizeof(CONFIG_HTTPS_HOSTNAME) - 1);
	if (err) {
		LOG_ERR("Failed to setup TLS hostname, err %d", errno);
		return err;
	}
	return 0;
}

static bool check_dns_ready(const char *hostname)
{
	int err;
	struct addrinfo *res = NULL;
	struct addrinfo hints = {
		.ai_family = AF_INET,
		.ai_socktype = SOCK_STREAM,
		.ai_flags = AI_NUMERICSERV,
	};

	err = getaddrinfo(hostname, HTTPS_PORT, &hints, &res);
	if (res) {
		freeaddrinfo(res);
	}

	return (err == 0);
}

static void send_http_request(void)
{
	int err;
	int fd = -1;
	char *p;
	int bytes;
	size_t off;
	struct addrinfo *res = NULL;
	struct addrinfo hints = {
		.ai_flags = AI_NUMERICSERV, /* Let getaddrinfo() set port */
		.ai_socktype = SOCK_STREAM,
		.ai_family = AF_INET, /* Force IPv4 to reduce DNS lookup time */
	};
	char peer_addr[INET6_ADDRSTRLEN];
	bool request_failed = false;

	if (!network_ready) {
		LOG_WRN("Network not ready, counting as HTTPS failure");
		https_req_total++;
		https_req_failures++;
		MEMFAULT_METRIC_SET_UNSIGNED(https_req_total_count, https_req_total);
		MEMFAULT_METRIC_SET_UNSIGNED(https_req_fail_count, https_req_failures);
		LOG_INF("HTTPS Request Test Metrics - Total: %u, Failures: %u",
			https_req_total, https_req_failures);
		return;
	}

	/* Increment total request count (both local and Memfault) */
	https_req_total++;
	MEMFAULT_METRIC_SET_UNSIGNED(https_req_total_count, https_req_total);

	LOG_INF("Looking up %s", CONFIG_HTTPS_HOSTNAME);

	err = getaddrinfo(CONFIG_HTTPS_HOSTNAME, HTTPS_PORT, &hints, &res);
	if (err) {
		LOG_ERR("getaddrinfo() failed, err %d", errno);
		request_failed = true;
		goto clean_up;
	}

	inet_ntop(res->ai_family,
		  &((struct sockaddr_in *)(res->ai_addr))->sin_addr, peer_addr,
		  INET6_ADDRSTRLEN);
	LOG_INF("Resolved %s (%s)", peer_addr, net_family2str(res->ai_family));

	if (IS_ENABLED(CONFIG_SAMPLE_TFM_MBEDTLS)) {
		fd = socket(res->ai_family, SOCK_STREAM | SOCK_NATIVE_TLS,
			    IPPROTO_TLS_1_2);
	} else {
		fd = socket(res->ai_family, SOCK_STREAM, IPPROTO_TLS_1_2);
	}
	if (fd == -1) {
		LOG_ERR("socket() failed, err %d", errno);
		request_failed = true;
		goto clean_up;
	}

	/* Set socket timeouts to prevent hanging */
	struct timeval timeout = {
		.tv_sec = 30,
		.tv_usec = 0,
	};
	(void)setsockopt(fd, SOL_SOCKET, SO_RCVTIMEO, &timeout,
			 sizeof(timeout));
	(void)setsockopt(fd, SOL_SOCKET, SO_SNDTIMEO, &timeout,
			 sizeof(timeout));

	/* Setup TLS socket options */
	err = tls_setup(fd);
	if (err) {
		LOG_ERR("TLS setup failed");
		request_failed = true;
		goto clean_up;
	}

	LOG_INF("Connecting to %s:%d", CONFIG_HTTPS_HOSTNAME,
		ntohs(((struct sockaddr_in *)(res->ai_addr))->sin_port));
	err = connect(fd, res->ai_addr, res->ai_addrlen);
	if (err) {
		LOG_ERR("connect() failed, err: %d", errno);
		request_failed = true;
		goto clean_up;
	}

	off = 0;
	do {
		bytes = send(fd, &send_buf[off], HTTP_HEAD_LEN - off, 0);
		if (bytes < 0) {
			LOG_ERR("send() failed, err %d", errno);
			request_failed = true;
			goto clean_up;
		}
		off += bytes;
	} while (off < HTTP_HEAD_LEN);

	LOG_INF("Sent %d bytes", off);

	off = 0;
	do {
		bytes = recv(fd, &recv_buf[off], RECV_BUF_SIZE - off, 0);
		if (bytes < 0) {
			LOG_ERR("recv() failed, err %d", errno);
			request_failed = true;
			goto clean_up;
		}
		off += bytes;
	} while (bytes != 0 /* peer closed connection */);

	LOG_INF("Received %d bytes", off);

	/* Make sure recv_buf is NULL terminated (for safe use with strstr) */
	if (off < sizeof(recv_buf)) {
		recv_buf[off] = '\0';
	} else {
		recv_buf[sizeof(recv_buf) - 1] = '\0';
	}

	/* Print HTTP response */
	p = strstr(recv_buf, "\r\n");
	if (p) {
		off = p - recv_buf;
		recv_buf[off + 1] = '\0';
		LOG_INF("Response: %s", recv_buf);
	}

	LOG_DBG("Finished, closing socket");

clean_up:
	if (request_failed) {
		https_req_failures++;
		MEMFAULT_METRIC_SET_UNSIGNED(https_req_fail_count,
					     https_req_failures);
	}
	/* Log local metrics after each request */
	LOG_INF("HTTPS Request Test Metrics - Total: %u, Failures: %u",
		https_req_total, https_req_failures);

	if (fd >= 0) {
		/* Graceful shutdown - notify peer we're done sending */
		(void)zsock_shutdown(fd, ZSOCK_SHUT_RDWR);
		(void)close(fd);
		/* Small delay to allow TCP/TLS resources to be released */
		k_sleep(K_MSEC(100));
	}
	if (res) {
		freeaddrinfo(res);
	}
}

static void https_client_thread(void *arg1, void *arg2, void *arg3)
{
	ARG_UNUSED(arg1);
	ARG_UNUSED(arg2);
	ARG_UNUSED(arg3);

	uint32_t http_request_count = 1;
	int cert_provisioned = 0;

	LOG_INF("HTTPS client thread started");

	while (https_client_running) {
		/* Wait for network connection */
		k_sem_take(&https_thread_sem, K_FOREVER);

		if (!https_client_running) {
			break;
		}

		/* Verify network is actually ready */
		if (!network_ready) {
			LOG_WRN("Network not ready after semaphore signal, "
				"skipping");
			continue;
		}

		/* Provision certificates once when first connected */
		if (!cert_provisioned) {
			int err = cert_provision();
			if (err) {
				LOG_ERR("Certificate provisioning failed: %d",
					err);
				network_ready = false;
				continue;
			}
			cert_provisioned = 1;
			LOG_INF("Certificate provisioned successfully");
		}

		LOG_INF("Network ready, waiting for DNS resolver");

		/* Wait for DNS to be ready - check every 10 seconds, timeout
		 * after 5 minutes */
		int dns_wait_time = 0;
		const int dns_timeout = 300; /* 5 minutes */
		while (network_ready &&
		       !check_dns_ready(CONFIG_HTTPS_HOSTNAME)) {
			if (dns_wait_time >= dns_timeout) {
				LOG_ERR("DNS timeout after %d seconds for %s, "
					"continuing anyway",
					dns_timeout, CONFIG_HTTPS_HOSTNAME);
				break;
			}
			LOG_INF("DNS not ready for %s, checking again in %d "
				"seconds",
				CONFIG_HTTPS_HOSTNAME, DNS_CHECK_INTERVAL_SEC);
			k_sleep(K_SECONDS(DNS_CHECK_INTERVAL_SEC));
			dns_wait_time += DNS_CHECK_INTERVAL_SEC;
		}

		/* Verify network still ready after DNS checks */
		if (!network_ready) {
			LOG_WRN("Network disconnected during DNS wait, "
				"aborting");
			continue;
		}

		if (dns_wait_time < dns_timeout) {
			LOG_INF("DNS ready for %s after %d seconds, sending "
				"HTTPS requests every %d seconds",
				CONFIG_HTTPS_HOSTNAME, dns_wait_time,
				HTTPS_REQUEST_INTERVAL_SEC);
		} else {
			LOG_WRN("Starting HTTPS operations without DNS "
				"confirmation");
		}
		/* Keep running test cycle regardless of network state;
		 * send_http_request() counts offline attempts as failures.
		 */
		while (https_client_running) {
			send_http_request();
			LOG_INF("HTTP request count: %d", http_request_count++);

			/* Sleep for the configured interval */
			k_sleep(K_SECONDS(HTTPS_REQUEST_INTERVAL_SEC));
		}

		LOG_INF("HTTPS client stopped");
	}

	LOG_INF("HTTPS client thread exiting");
}

K_THREAD_DEFINE(https_client_tid, CONFIG_HTTPS_CLIENT_STACK_SIZE,
		https_client_thread, NULL, NULL, NULL,
		CONFIG_HTTPS_CLIENT_THREAD_PRIORITY, 0, 0);

int https_client_init(void)
{
	LOG_INF("HTTPS client initialized");
	https_client_running = true;
	return 0;
}

void https_client_notify_connected(void)
{
	if (https_client_running && !network_ready) {
		LOG_INF("Network connected, notifying HTTPS client");
		network_ready = true;
		k_sem_give(&https_thread_sem);
	} else if (network_ready) {
		LOG_DBG("Network already marked as ready, skipping duplicate "
			"notification");
	}
}

void https_client_notify_disconnected(void)
{
	LOG_INF("Network disconnected, pausing HTTPS client");
	network_ready = false;
}
```

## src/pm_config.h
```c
/*
 * SPDX-License-Identifier: LicenseRef-Nordic-5-Clause
 *
 * Compatibility shim for projects migrated from Partition Manager to DTS.
 *
 * NCS 3.3 deprecates Partition Manager, but some nRF libraries still include
 * <pm_config.h>. This header exposes a minimal PM-style macro set derived from
 * fixed-partition devicetree nodes so those libraries continue to build.
 */

#ifndef APP_PM_CONFIG_COMPAT_H_
#define APP_PM_CONFIG_COMPAT_H_

#include <zephyr/devicetree.h>
#include <zephyr/storage/flash_map.h>

#if DT_NODE_EXISTS(DT_NODELABEL(boot_partition))
#define PM_MCUBOOT_ADDRESS PARTITION_OFFSET(boot_partition)
#define PM_MCUBOOT_SIZE PARTITION_SIZE(boot_partition)
#define PM_MCUBOOT_ID PARTITION_ID(boot_partition)
#endif

#if DT_NODE_EXISTS(DT_NODELABEL(slot0_partition))
#define PM_MCUBOOT_PRIMARY_ADDRESS PARTITION_OFFSET(slot0_partition)
#define PM_MCUBOOT_PRIMARY_SIZE PARTITION_SIZE(slot0_partition)
#define PM_MCUBOOT_PRIMARY_ID PARTITION_ID(slot0_partition)
#endif

#if DT_NODE_EXISTS(DT_NODELABEL(slot1_partition))
#define PM_MCUBOOT_SECONDARY_ADDRESS PARTITION_OFFSET(slot1_partition)
#define PM_MCUBOOT_SECONDARY_SIZE PARTITION_SIZE(slot1_partition)
#define PM_MCUBOOT_SECONDARY_ID PARTITION_ID(slot1_partition)
#endif

#if DT_NODE_EXISTS(DT_NODELABEL(storage_partition))
#define PM_SETTINGS_STORAGE_ADDRESS PARTITION_OFFSET(storage_partition)
#define PM_SETTINGS_STORAGE_SIZE PARTITION_SIZE(storage_partition)
#define PM_SETTINGS_STORAGE_ID PARTITION_ID(storage_partition)
#endif

#if DT_NODE_EXISTS(DT_NODELABEL(memfault_storage))
#define MEMFAULT_STORAGE memfault_storage
#define PM_MEMFAULT_STORAGE_ADDRESS PARTITION_OFFSET(memfault_storage)
#define PM_MEMFAULT_STORAGE_SIZE PARTITION_SIZE(memfault_storage)
#define PM_MEMFAULT_STORAGE_ID PARTITION_ID(memfault_storage)
#endif

#if DT_NODE_EXISTS(DT_NODELABEL(memfault_coredump_partition))
#define MEMFAULT_COREDUMP_PARTITION memfault_coredump_partition
#define PM_MEMFAULT_COREDUMP_PARTITION_ADDRESS \
	PARTITION_OFFSET(memfault_coredump_partition)
#define PM_MEMFAULT_COREDUMP_PARTITION_SIZE \
	PARTITION_SIZE(memfault_coredump_partition)
#define PM_MEMFAULT_COREDUMP_PARTITION_ID \
	PARTITION_ID(memfault_coredump_partition)
#endif

#endif /* APP_PM_CONFIG_COMPAT_H_ */
```

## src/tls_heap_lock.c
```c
/*
 * Copyright (c) 2026 Nordic Semiconductor ASA
 *
 * SPDX-License-Identifier: LicenseRef-Nordic-5-Clause
 */

#include "tls_heap_lock.h"

K_MUTEX_DEFINE(tls_heap_lock);
```
